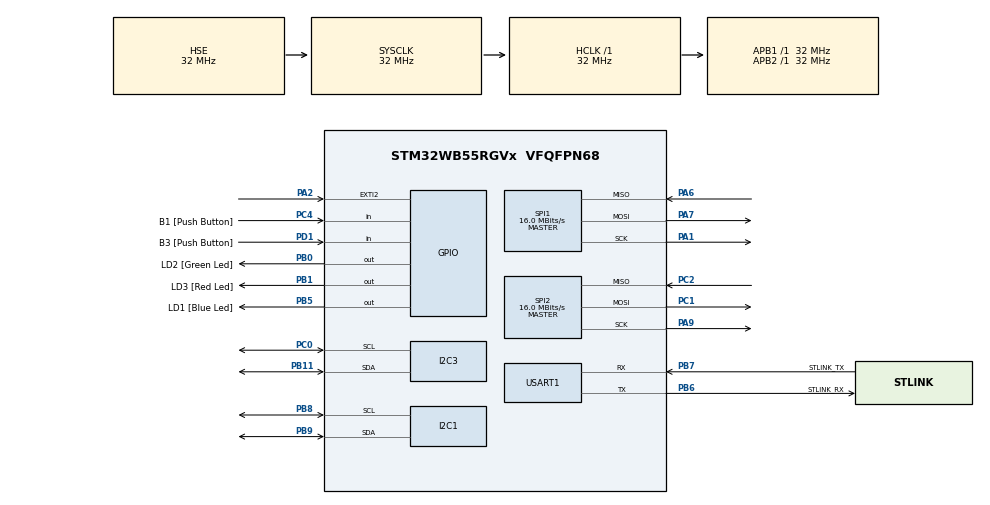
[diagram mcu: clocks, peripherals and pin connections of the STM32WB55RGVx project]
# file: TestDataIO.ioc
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FATFS._LFN_UNICODE=1
FATFS._STRF_ENCODE=1
FATFS._USE_FIND=1
FATFS._USE_LFN=1
I2C1.Speed=100
I2C1.Timing=0x00707CBB
I2C3.Timing=0x00707CBB
Mcu.Family=STM32WB
Mcu.Name=STM32WB55RGVx
Mcu.Package=VFQFPN68
NVIC.EXTI2_IRQn=true\:0\:0\:false\:false\:true\:true\:true
NVIC.I2C1_ER_IRQn=true\:0\:0\:false\:false\:true\:true\:true
NVIC.I2C1_EV_IRQn=true\:0\:0\:false\:false\:true\:true\:true
NVIC.I2C3_ER_IRQn=true\:0\:0\:false\:false\:true\:true\:true
NVIC.I2C3_EV_IRQn=true\:0\:0\:false\:false\:true\:true\:true
NVIC.PriorityGroup=NVIC_PRIORITYGROUP_4
NVIC.SPI1_IRQn=true\:0\:0\:false\:false\:true\:true\:true
NVIC.SPI2_IRQn=true\:0\:0\:false\:false\:true\:true\:true
NVIC.TIM2_IRQn=true\:0\:0\:false\:false\:true\:true\:true
OSC_IN.Mode=HSE-External-Oscillator
OSC_IN.Signal=RCC_OSC_IN
OSC_OUT.Mode=HSE-External-Oscillator
OSC_OUT.Signal=RCC_OSC_OUT
PA1.Mode=Full_Duplex_Master
PA1.Signal=SPI1_SCK
PA11.Signal=USB_DM
PA12.Signal=USB_DP
PA13.GPIO_Label=JTMS
PA13.Mode=Trace_Asynchronous_SW
PA13.Signal=SYS_JTMS-SWDIO
PA14.GPIO_Label=JTCK
PA14.Mode=Trace_Asynchronous_SW
PA14.Signal=SYS_JTCK-SWCLK
PA2.Signal=GPXTI2
PA4.Signal=SPI1_NSS
PA6.Mode=Full_Duplex_Master
PA6.Signal=SPI1_MISO
PA7.Mode=Full_Duplex_Master
PA7.Signal=SPI1_MOSI
PA9.Mode=Full_Duplex_Master
PA9.Signal=SPI2_SCK
PB0.GPIO_Label=LD2 [Green Led]
PB0.Signal=GPIO_Output
PB1.GPIO_Label=LD3 [Red Led]
PB1.Signal=GPIO_Output
PB11.Mode=I2C
PB11.Signal=I2C3_SDA
PB3.GPIO_Label=JTDO
PB3.Mode=Trace_Asynchronous_SW
PB3.Signal=SYS_JTDO-SWO
PB5.GPIO_Label=LD1 [Blue Led]
PB5.Signal=GPIO_Output
PB6.GPIO_Label=STLINK_RX
PB6.GPIO_PuPd=GPIO_PULLUP
PB6.Mode=Asynchronous
PB6.Signal=USART1_TX
PB7.GPIO_Label=STLINK_TX
PB7.GPIO_PuPd=GPIO_PULLUP
PB7.Mode=Asynchronous
PB7.Signal=USART1_RX
PB8.Mode=I2C
PB8.Signal=I2C1_SCL
PB9.Mode=I2C
PB9.Signal=I2C1_SDA
PC0.Mode=I2C
PC0.Signal=I2C3_SCL
PC1.Mode=Full_Duplex_Master
PC1.Signal=SPI2_MOSI
PC13.Mode=SYS_WakeUp1
PC13.Signal=SYS_WKUP2
PC14-OSC32_IN.Mode=LSE-External-Oscillator
PC14-OSC32_IN.Signal=RCC_OSC32_IN
PC15-OSC32_OUT.Mode=LSE-External-Oscillator
PC15-OSC32_OUT.Signal=RCC_OSC32_OUT
PC2.Mode=Full_Duplex_Master
PC2.Signal=SPI2_MISO
PC4.GPIO_Label=B1 [Push Button]
PC4.Signal=GPIO_Input
PD0.Signal=SPI2_NSS
PD1.GPIO_Label=B3 [Push Button]
PD1.Signal=GPIO_Input
ProjectManager.HeapSize=0x27000
ProjectManager.StackSize=0x1200
ProjectManager.TargetToolchain=EWARM V8.32
RCC.ADCFreq_Value=48000000
RCC.AHBFreq_Value=32000000
RCC.APB1Freq_Value=32000000
RCC.APB1TimFreq_Value=32000000
RCC.APB2Freq_Value=32000000
RCC.APB2TimFreq_Value=32000000
RCC.APB3Freq_Value=16000000
RCC.CortexFreq_Value=32000000
RCC.HCLKFreq_Value=32000000
RCC.HSE_VALUE=32000000
RCC.HSI48_VALUE=48000000
RCC.HSI_VALUE=16000000
RCC.PLLN=32
RCC.PLLSAI1N=24
RCC.SMPSCLockSelectionVirtual=RCC_SMPSCLKSOURCE_HSI
RCC.SMPSCLockSelectionVirtualVirtual=RCC_SMPSCLKSOURCE_HSI
RCC.SMPSDivider=1
RCC.SYSCLKFreq_VALUE=32000000
RCC.SYSCLKSource=RCC_SYSCLKSOURCE_HSE
RCC.USBFreq_Value=48000000
RCC.VCOOutputFreq_Value=128000000
SPI1.BaudRatePrescaler=SPI_BAUDRATEPRESCALER_2
SPI1.CLKPhase=SPI_PHASE_1EDGE
SPI1.CalculateBaudRate=16.0 MBits/s
SPI1.DataSize=SPI_DATASIZE_8BIT
SPI1.Direction=SPI_DIRECTION_2LINES
SPI1.Mode=SPI_MODE_MASTER
SPI1.VirtualType=VM_MASTER
SPI2.BaudRatePrescaler=SPI_BAUDRATEPRESCALER_2
SPI2.CLKPolarity=SPI_POLARITY_LOW
SPI2.CalculateBaudRate=16.0 MBits/s
SPI2.DataSize=SPI_DATASIZE_8BIT
SPI2.Direction=SPI_DIRECTION_2LINES
SPI2.Mode=SPI_MODE_MASTER
SPI2.VirtualType=VM_MASTER
TIM2.Period=1
TIM2.Prescaler=64000
USART1.VirtualMode-Asynchronous=VM_ASYNC
USART1.WordLength=WORDLENGTH_8B
VP_FATFS_VS_Generic.Mode=User_defined
VP_TIM2_VS_ClockSourceINT.Mode=Internal
board=NUCLEO-WB55RG

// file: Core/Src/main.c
/* USER CODE BEGIN Header */
/**
  ******************************************************************************
  * @file           : main.c
  * @brief          : Main program body
  ******************************************************************************
  * @attention
  *
  * <h2><center>&copy; Copyright (c) 2021 STMicroelectronics.
  * All rights reserved.</center></h2>
  *
  * This software component is licensed by ST under Ultimate Liberty license
  * SLA0044, the "License"; You may not use this file except in compliance with
  * the License. You may obtain a copy of the License at:
  *                             www.st.com/SLA0044
  *
  ******************************************************************************
  */
/* USER CODE END Header */
#include "main.h"
#include "app_fatfs.h"

I2C_HandleTypeDef hi2c1;
I2C_HandleTypeDef hi2c3;

SPI_HandleTypeDef hspi1;
SPI_HandleTypeDef hspi2;

TIM_HandleTypeDef htim2;

UART_HandleTypeDef huart1;

void SystemClock_Config(void);
static void MX_GPIO_Init(void);
static void MX_USART1_UART_Init(void);
static void MX_I2C1_Init(void);
static void MX_TIM2_Init(void);
static void MX_SPI1_Init(void);
static void MX_SPI2_Init(void);
static void MX_I2C3_Init(void);

int _main(void)
{

  /* MCU Configuration--------------------------------------------------------*/

  /* Reset of all peripherals, Initializes the Flash interface and the Systick. */
  HAL_Init();

  /* Configure the system clock */
  SystemClock_Config();

  /* Initialize all configured peripherals */
  MX_GPIO_Init();
  MX_USART1_UART_Init();
  MX_I2C1_Init();
  MX_TIM2_Init();
  if (MX_FATFS_Init() != APP_OK) {
    Error_Handler();
  }
  MX_SPI1_Init();
  MX_SPI2_Init();
  MX_I2C3_Init();

  /* Infinite loop */
  /* USER CODE BEGIN WHILE */
  //while (1)
  {
    /* USER CODE END WHILE */

    /* USER CODE BEGIN 3 */
  }
  return 1;
  /* USER CODE END 3 */
}

void SystemClock_Config(void)
{
  RCC_OscInitTypeDef RCC_OscInitStruct = {0};
  RCC_ClkInitTypeDef RCC_ClkInitStruct = {0};
  RCC_PeriphCLKInitTypeDef PeriphClkInitStruct = {0};

  /** Configure the main internal regulator output voltage
  */
  __HAL_PWR_VOLTAGESCALING_CONFIG(PWR_REGULATOR_VOLTAGE_SCALE1);
  /** Initializes the RCC Oscillators according to the specified parameters
  * in the RCC_OscInitTypeDef structure.
  */
  RCC_OscInitStruct.OscillatorType = RCC_OSCILLATORTYPE_HSI|RCC_OSCILLATORTYPE_HSE;
  RCC_OscInitStruct.HSEState = RCC_HSE_ON;
  RCC_OscInitStruct.HSIState = RCC_HSI_ON;
  RCC_OscInitStruct.HSICalibrationValue = RCC_HSICALIBRATION_DEFAULT;
  RCC_OscInitStruct.PLL.PLLState = RCC_PLL_NONE;
  if (HAL_RCC_OscConfig(&RCC_OscInitStruct) != HAL_OK)
  {
    Error_Handler();
  }
  /** Configure the SYSCLKSource, HCLK, PCLK1 and PCLK2 clocks dividers
  */
  RCC_ClkInitStruct.ClockType = RCC_CLOCKTYPE_HCLK4|RCC_CLOCKTYPE_HCLK2
                              |RCC_CLOCKTYPE_HCLK|RCC_CLOCKTYPE_SYSCLK
                              |RCC_CLOCKTYPE_PCLK1|RCC_CLOCKTYPE_PCLK2;
  RCC_ClkInitStruct.SYSCLKSource = RCC_SYSCLKSOURCE_HSE;
  RCC_ClkInitStruct.AHBCLKDivider = RCC_SYSCLK_DIV1;
  RCC_ClkInitStruct.APB1CLKDivider = RCC_HCLK_DIV1;
  RCC_ClkInitStruct.APB2CLKDivider = RCC_HCLK_DIV1;
  RCC_ClkInitStruct.AHBCLK2Divider = RCC_SYSCLK_DIV1;
  RCC_ClkInitStruct.AHBCLK4Divider = RCC_SYSCLK_DIV1;

  if (HAL_RCC_ClockConfig(&RCC_ClkInitStruct, FLASH_LATENCY_1) != HAL_OK)
  {
    Error_Handler();
  }
  /** Initializes the peripherals clocks
  */
  PeriphClkInitStruct.PeriphClockSelection = RCC_PERIPHCLK_SMPS|RCC_PERIPHCLK_USART1
                              |RCC_PERIPHCLK_I2C1|RCC_PERIPHCLK_I2C3;
  PeriphClkInitStruct.Usart1ClockSelection = RCC_USART1CLKSOURCE_PCLK2;
  PeriphClkInitStruct.I2c1ClockSelection = RCC_I2C1CLKSOURCE_PCLK1;
  PeriphClkInitStruct.I2c3ClockSelection = RCC_I2C3CLKSOURCE_PCLK1;
  PeriphClkInitStruct.SmpsClockSelection = RCC_SMPSCLKSOURCE_HSI;
  PeriphClkInitStruct.SmpsDivSelection = RCC_SMPSCLKDIV_RANGE0;
  if (HAL_RCCEx_PeriphCLKConfig(&PeriphClkInitStruct) != HAL_OK)
  {
    Error_Handler();
  }
}

static void MX_I2C1_Init(void)
{

  hi2c1.Instance = I2C1;
  hi2c1.Init.Timing = 0x00707CBB;
  hi2c1.Init.OwnAddress1 = 0;
  hi2c1.Init.AddressingMode = I2C_ADDRESSINGMODE_7BIT;
  hi2c1.Init.DualAddressMode = I2C_DUALADDRESS_DISABLE;
  hi2c1.Init.OwnAddress2 = 0;
  hi2c1.Init.OwnAddress2Masks = I2C_OA2_NOMASK;
  hi2c1.Init.GeneralCallMode = I2C_GENERALCALL_DISABLE;
  hi2c1.Init.NoStretchMode = I2C_NOSTRETCH_DISABLE;
  if (HAL_I2C_Init(&hi2c1) != HAL_OK)
  {
    Error_Handler();
  }
  /** Configure Analogue filter
  */
  if (HAL_I2CEx_ConfigAnalogFilter(&hi2c1, I2C_ANALOGFILTER_ENABLE) != HAL_OK)
  {
    Error_Handler();
  }
  /** Configure Digital filter
  */
  if (HAL_I2CEx_ConfigDigitalFilter(&hi2c1, 0) != HAL_OK)
  {
    Error_Handler();
  }

}

static void MX_I2C3_Init(void)
{

  hi2c3.Instance = I2C3;
  hi2c3.Init.Timing = 0x00707CBB;
  hi2c3.Init.OwnAddress1 = 0;
  hi2c3.Init.AddressingMode = I2C_ADDRESSINGMODE_7BIT;
  hi2c3.Init.DualAddressMode = I2C_DUALADDRESS_DISABLE;
  hi2c3.Init.OwnAddress2 = 0;
  hi2c3.Init.OwnAddress2Masks = I2C_OA2_NOMASK;
  hi2c3.Init.GeneralCallMode = I2C_GENERALCALL_DISABLE;
  hi2c3.Init.NoStretchMode = I2C_NOSTRETCH_DISABLE;
  if (HAL_I2C_Init(&hi2c3) != HAL_OK)
  {
    Error_Handler();
  }
  /** Configure Analogue filter
  */
  if (HAL_I2CEx_ConfigAnalogFilter(&hi2c3, I2C_ANALOGFILTER_ENABLE) != HAL_OK)
  {
    Error_Handler();
  }
  /** Configure Digital filter
  */
  if (HAL_I2CEx_ConfigDigitalFilter(&hi2c3, 0) != HAL_OK)
  {
    Error_Handler();
  }

}

static void MX_SPI1_Init(void)
{

  /* SPI1 parameter configuration*/
  hspi1.Instance = SPI1;
  hspi1.Init.Mode = SPI_MODE_MASTER;
  hspi1.Init.Direction = SPI_DIRECTION_2LINES;
  hspi1.Init.DataSize = SPI_DATASIZE_8BIT;
  hspi1.Init.CLKPolarity = SPI_POLARITY_LOW;
  hspi1.Init.CLKPhase = SPI_PHASE_1EDGE;
  hspi1.Init.NSS = SPI_NSS_SOFT;
  hspi1.Init.BaudRatePrescaler = SPI_BAUDRATEPRESCALER_2;
  hspi1.Init.FirstBit = SPI_FIRSTBIT_MSB;
  hspi1.Init.TIMode = SPI_TIMODE_DISABLE;
  hspi1.Init.CRCCalculation = SPI_CRCCALCULATION_DISABLE;
  hspi1.Init.CRCPolynomial = 7;
  hspi1.Init.CRCLength = SPI_CRC_LENGTH_DATASIZE;
  hspi1.Init.NSSPMode = SPI_NSS_PULSE_ENABLE;
  if (HAL_SPI_Init(&hspi1) != HAL_OK)
  {
    Error_Handler();
  }

}

static void MX_SPI2_Init(void)
{

  /* SPI2 parameter configuration*/
  hspi2.Instance = SPI2;
  hspi2.Init.Mode = SPI_MODE_MASTER;
  hspi2.Init.Direction = SPI_DIRECTION_2LINES;
  hspi2.Init.DataSize = SPI_DATASIZE_8BIT;
  hspi2.Init.CLKPolarity = SPI_POLARITY_LOW;
  hspi2.Init.CLKPhase = SPI_PHASE_1EDGE;
  hspi2.Init.NSS = SPI_NSS_SOFT;
  hspi2.Init.BaudRatePrescaler = SPI_BAUDRATEPRESCALER_2;
  hspi2.Init.FirstBit = SPI_FIRSTBIT_MSB;
  hspi2.Init.TIMode = SPI_TIMODE_DISABLE;
  hspi2.Init.CRCCalculation = SPI_CRCCALCULATION_DISABLE;
  hspi2.Init.CRCPolynomial = 7;
  hspi2.Init.CRCLength = SPI_CRC_LENGTH_DATASIZE;
  hspi2.Init.NSSPMode = SPI_NSS_PULSE_ENABLE;
  if (HAL_SPI_Init(&hspi2) != HAL_OK)
  {
    Error_Handler();
  }

}

static void MX_TIM2_Init(void)
{

  TIM_ClockConfigTypeDef sClockSourceConfig = {0};
  TIM_MasterConfigTypeDef sMasterConfig = {0};

  htim2.Instance = TIM2;
  htim2.Init.Prescaler = 64000;
  htim2.Init.CounterMode = TIM_COUNTERMODE_UP;
  htim2.Init.Period = 1;
  htim2.Init.ClockDivision = TIM_CLOCKDIVISION_DIV1;
  htim2.Init.AutoReloadPreload = TIM_AUTORELOAD_PRELOAD_DISABLE;
  if (HAL_TIM_Base_Init(&htim2) != HAL_OK)
  {
    Error_Handler();
  }
  sClockSourceConfig.ClockSource = TIM_CLOCKSOURCE_INTERNAL;
  if (HAL_TIM_ConfigClockSource(&htim2, &sClockSourceConfig) != HAL_OK)
  {
    Error_Handler();
  }
  sMasterConfig.MasterOutputTrigger = TIM_TRGO_RESET;
  sMasterConfig.MasterSlaveMode = TIM_MASTERSLAVEMODE_DISABLE;
  if (HAL_TIMEx_MasterConfigSynchronization(&htim2, &sMasterConfig) != HAL_OK)
  {
    Error_Handler();
  }
  /* USER CODE BEGIN TIM2_Init 2 */
  HAL_TIM_Base_Start_IT(&htim2);
  /* USER CODE END TIM2_Init 2 */

}

static void MX_USART1_UART_Init(void)
{

  huart1.Instance = USART1;
  huart1.Init.BaudRate = 115200;
  huart1.Init.WordLength = UART_WORDLENGTH_8B;
  huart1.Init.StopBits = UART_STOPBITS_1;
  huart1.Init.Parity = UART_PARITY_NONE;
  huart1.Init.Mode = UART_MODE_TX_RX;
  huart1.Init.HwFlowCtl = UART_HWCONTROL_NONE;
  huart1.Init.OverSampling = UART_OVERSAMPLING_16;
  huart1.Init.OneBitSampling = UART_ONE_BIT_SAMPLE_DISABLE;
  huart1.Init.ClockPrescaler = UART_PRESCALER_DIV1;
  huart1.AdvancedInit.AdvFeatureInit = UART_ADVFEATURE_NO_INIT;
  if (HAL_UART_Init(&huart1) != HAL_OK)
  {
    Error_Handler();
  }
  if (HAL_UARTEx_SetTxFifoThreshold(&huart1, UART_TXFIFO_THRESHOLD_1_8) != HAL_OK)
  {
    Error_Handler();
  }
  if (HAL_UARTEx_SetRxFifoThreshold(&huart1, UART_RXFIFO_THRESHOLD_1_8) != HAL_OK)
  {
    Error_Handler();
  }
  if (HAL_UARTEx_DisableFifoMode(&huart1) != HAL_OK)
  {
    Error_Handler();
  }

}

static void MX_GPIO_Init(void)
{
  GPIO_InitTypeDef GPIO_InitStruct = {0};

  /* GPIO Ports Clock Enable */
  __HAL_RCC_GPIOC_CLK_ENABLE();
  __HAL_RCC_GPIOB_CLK_ENABLE();
  __HAL_RCC_GPIOA_CLK_ENABLE();
  __HAL_RCC_GPIOD_CLK_ENABLE();

  /*Configure GPIO pin Output Level */
  HAL_GPIO_WritePin(GPIOB, LD2_Pin|LD3_Pin|LD1_Pin, GPIO_PIN_RESET);

  /*Configure GPIO pin : PA2 */
  GPIO_InitStruct.Pin = GPIO_PIN_2;
  GPIO_InitStruct.Mode = GPIO_MODE_IT_RISING;
  GPIO_InitStruct.Pull = GPIO_NOPULL;
  HAL_GPIO_Init(GPIOA, &GPIO_InitStruct);

  /*Configure GPIO pin : B1_Pin */
  GPIO_InitStruct.Pin = B1_Pin;
  GPIO_InitStruct.Mode = GPIO_MODE_INPUT;
  GPIO_InitStruct.Pull = GPIO_NOPULL;
  HAL_GPIO_Init(B1_GPIO_Port, &GPIO_InitStruct);

  /*Configure GPIO pins : LD2_Pin LD3_Pin LD1_Pin */
  GPIO_InitStruct.Pin = LD2_Pin|LD3_Pin|LD1_Pin;
  GPIO_InitStruct.Mode = GPIO_MODE_OUTPUT_PP;
  GPIO_InitStruct.Pull = GPIO_NOPULL;
  GPIO_InitStruct.Speed = GPIO_SPEED_FREQ_LOW;
  HAL_GPIO_Init(GPIOB, &GPIO_InitStruct);

  /*Configure GPIO pins : PA11 PA12 */
  GPIO_InitStruct.Pin = GPIO_PIN_11|GPIO_PIN_12;
  GPIO_InitStruct.Mode = GPIO_MODE_AF_PP;
  GPIO_InitStruct.Pull = GPIO_NOPULL;
  GPIO_InitStruct.Speed = GPIO_SPEED_FREQ_LOW;
  GPIO_InitStruct.Alternate = GPIO_AF10_USB;
  HAL_GPIO_Init(GPIOA, &GPIO_InitStruct);

  /*Configure GPIO pin : B3_Pin */
  GPIO_InitStruct.Pin = B3_Pin;
  GPIO_InitStruct.Mode = GPIO_MODE_INPUT;
  GPIO_InitStruct.Pull = GPIO_NOPULL;
  HAL_GPIO_Init(B3_GPIO_Port, &GPIO_InitStruct);

  /* EXTI interrupt init*/
  HAL_NVIC_SetPriority(EXTI2_IRQn, 0, 0);
  HAL_NVIC_EnableIRQ(EXTI2_IRQn);

}

void Error_Handler(void)
{
  __disable_irq();
  while (1)
  {
  }
}

/************************ (C) COPYRIGHT STMicroelectronics *****END OF FILE****/
